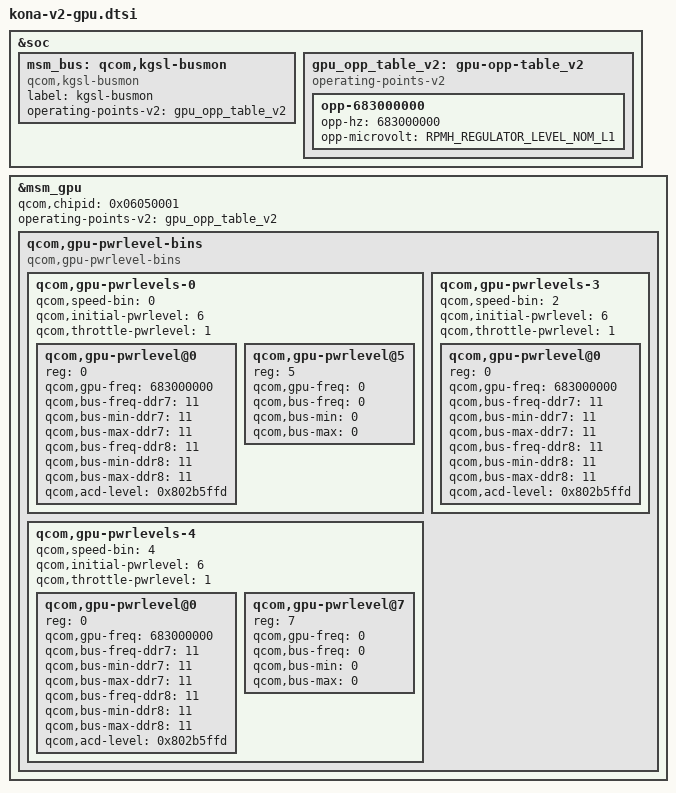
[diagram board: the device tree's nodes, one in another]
&soc {
	msm_bus: qcom,kgsl-busmon {
		label = "kgsl-busmon";
		compatible = "qcom,kgsl-busmon";
		operating-points-v2 = <&gpu_opp_table_v2>;
	};

	gpu_opp_table_v2: gpu-opp-table_v2 {
		compatible = "operating-points-v2";

		opp-683000000 {
			opp-hz = /bits/ 64 <683000000>;
			opp-microvolt = <RPMH_REGULATOR_LEVEL_NOM_L1>;
		};
	};
};

&msm_gpu {
	qcom,chipid = <0x06050001>;

	/* GPU OPP data */
	operating-points-v2 = <&gpu_opp_table_v2>;

	/delete-property/qcom,initial-pwrlevel;
	/delete-node/qcom,gpu-pwrlevels;

	/* Power levels bins */
	qcom,gpu-pwrlevel-bins {
		compatible="qcom,gpu-pwrlevel-bins";
		#address-cells = <1>;
		#size-cells = <0>;

		qcom,gpu-pwrlevels-0 {
			#address-cells = <1>;
			#size-cells = <0>;
			qcom,speed-bin = <0>;
			qcom,initial-pwrlevel = <6>;
			qcom,throttle-pwrlevel = <1>;

			qcom,gpu-pwrlevel@0 {
				reg = <0>;
				qcom,gpu-freq = <683000000>;
				qcom,bus-freq-ddr7 = <11>;
				qcom,bus-min-ddr7 = <11>;
				qcom,bus-max-ddr7 = <11>;

				qcom,bus-freq-ddr8 = <11>;
				qcom,bus-min-ddr8 = <11>;
				qcom,bus-max-ddr8 = <11>;

				qcom,acd-level = <0x802b5ffd>;
			};

			qcom,gpu-pwrlevel@0 {
				reg = <0>;
				qcom,gpu-freq = <683000000>;
				qcom,bus-freq-ddr7 = <11>;
				qcom,bus-min-ddr7 = <11>;
				qcom,bus-max-ddr7 = <11>;

				qcom,bus-freq-ddr8 = <11>;
				qcom,bus-min-ddr8 = <11>;
				qcom,bus-max-ddr8 = <11>;

				qcom,acd-level = <0x802b5ffd>;
			};

			qcom,gpu-pwrlevel@5 {
				reg = <5>;
				qcom,gpu-freq = <0>;
				qcom,bus-freq = <0>;
				qcom,bus-min = <0>;
				qcom,bus-max = <0>;
			};
		};

		qcom,gpu-pwrlevels-3 {
			#address-cells = <1>;
			#size-cells = <0>;
			qcom,speed-bin = <2>;
			qcom,initial-pwrlevel = <6>;
			qcom,throttle-pwrlevel = <1>;

			qcom,gpu-pwrlevel@0 {
				reg = <0>;
				qcom,gpu-freq = <683000000>;
				qcom,bus-freq-ddr7 = <11>;
				qcom,bus-min-ddr7 = <11>;
				qcom,bus-max-ddr7 = <11>;

				qcom,bus-freq-ddr8 = <11>;
				qcom,bus-min-ddr8 = <11>;
				qcom,bus-max-ddr8 = <11>;

				qcom,acd-level = <0x802b5ffd>;
			};
		};

		qcom,gpu-pwrlevels-4 {
			#address-cells = <1>;
			#size-cells = <0>;
			qcom,speed-bin = <4>;
			qcom,initial-pwrlevel = <6>;
			qcom,throttle-pwrlevel = <1>;

			qcom,gpu-pwrlevel@0 {
				reg = <0>;
				qcom,gpu-freq = <683000000>;
				qcom,bus-freq-ddr7 = <11>;
				qcom,bus-min-ddr7 = <11>;
				qcom,bus-max-ddr7 = <11>;

				qcom,bus-freq-ddr8 = <11>;
				qcom,bus-min-ddr8 = <11>;
				qcom,bus-max-ddr8 = <11>;

				qcom,acd-level = <0x802b5ffd>;
			};

			qcom,gpu-pwrlevel@7 {
				reg = <7>;
				qcom,gpu-freq = <0>;
				qcom,bus-freq = <0>;
				qcom,bus-min = <0>;
				qcom,bus-max = <0>;
			};
		};
	};
};
